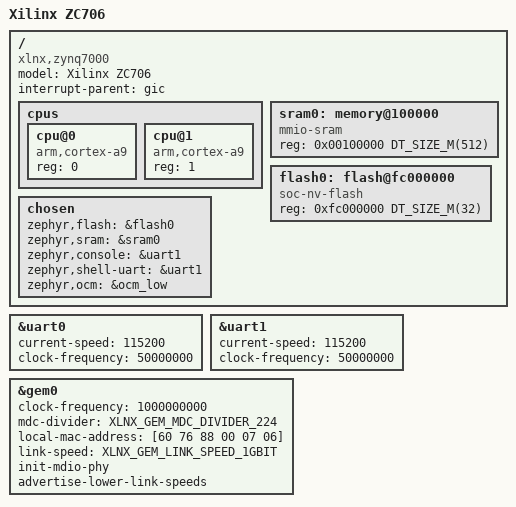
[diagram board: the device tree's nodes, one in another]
/*
 * Copyright (c) 2021 Weidmueller Interface GmbH & Co. KG
 * SPDX-License-Identifier: Apache-2.0
 */

/dts-v1/;

#include <xilinx/zynq7000.dtsi>
#include <dt-bindings/ethernet/xlnx_gem.h>

/ {
	model = "Xilinx ZC706";
	compatible = "xlnx,zynq7000";
	interrupt-parent = <&gic>;

	cpus {
		#address-cells = <1>;
		#size-cells = <0>;

		cpu@0 {
			device_type = "cpu";
			compatible = "arm,cortex-a9";
			reg = <0>;
		};

		cpu@1 {
			device_type = "cpu";
			compatible = "arm,cortex-a9";
			reg = <1>;
		};
	};

	sram0: memory@100000 {
		compatible = "mmio-sram";
		reg = <0x00100000 DT_SIZE_M(512)>;
	};

	flash0: flash@fc000000{
		compatible = "soc-nv-flash";
		reg = <0xfc000000 DT_SIZE_M(32)>;
	};

	chosen {
		zephyr,flash      = &flash0;
		zephyr,sram       = &sram0;
		zephyr,console    = &uart1;
		zephyr,shell-uart = &uart1;
		zephyr,ocm        = &ocm_low;
	};
};

&uart0 {
	status = "okay";
	current-speed = <115200>;
	clock-frequency = <50000000>;
};

&uart1 {
	status = "okay";
	current-speed = <115200>;
	clock-frequency = <50000000>;
};

&gem0 {
	status = "okay";
	clock-frequency = <1000000000>;
	mdc-divider = <XLNX_GEM_MDC_DIVIDER_224>;
	local-mac-address = [60 76 88 00 07 06];
	link-speed = <XLNX_GEM_LINK_SPEED_1GBIT>;
	init-mdio-phy;
	advertise-lower-link-speeds;
};
